# M2Sxxx register map
Vendor: Microsemi; Series: SmartFusion2; File version: 2.0.32
CPU: CM3 r2p1, little endian, MPU, no FPU, 4 interrupt priority bits
Registers are 32-bit, read-write, no defined reset value unless marked. A register's access mark holds for its fields unless they carry their own. Offsets are from the block's base; [hi:lo] are bit positions; {n}, {i} and the like mark numbered series; 'fields as' and 'values as' point back to an identical list.

## MMUART_0 — No description provided for this peripheral
Base 0x40000000
Same registers: MMUART_1 0x40010000
0x00 RBR — Receiver buffer register
  [12] RBR ro — This register holds the receive data bits for MMUART_x. The default value is unknown since the register is loaded with data in the receive FIFO. Bit 0 is the LSB and it is the first bit received. It may be configured as the MSB by configuring the E_MSB_RX bit in the MM1. The divisor latch access bit (DLAB), bit 7 of LCR, must be 0 to read this register. This register is read only. Writing to this register with the DLAB 0 changes the transmit holding register (THR) register value.
0x00 THR (alternate view of RBR) — Transmit holding register
  [7:0] THR wo — This register holds the data bits to be transmitted. Bit 0 is the LSB and is transmitted first. The MSB may be transmitted first, if it is configured with the E_MSB_TX bit in the MM1. The reset value is unknown since the register is loaded with data in the transmit FIFO. The DLAB, bit 7 of LCR, must be 0 to write to this register. This register is write only. Reading from this register with the DLAB 0 reads the RBR register value.
0x00 DLR (alternate view of RBR) — Divisor latch (LSB)
  [7:0] DLR — This divisor latch LSB register (DLR) holds the LSB of the integer divisor value used to calculate the baud rate. The baud rate can be calculated using EQ 1, 2, 3, or 4.
0x04 DMR — Divisor latch (MSB)
  [7:0] DMR — This divisor latch MSB register (DMR) holds the MSB of the integer divisor value used to calculate the baud rate. The baud rate can be calculated using EQ 1, 2, 3, or 4.
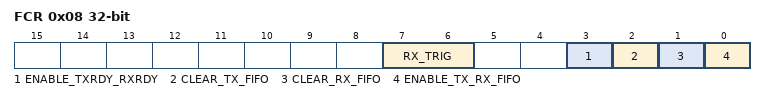
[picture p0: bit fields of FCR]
0x08 FCR — FIFO control register
  [7:6] RX_TRIG wo — These bits are used to set the trigger level for the Rx FIFO interrupt. Rx FIFO trigger level (bytes) are: 0b00: 1 byte 0b01: 4 bytes 0b10: 8 bytes 0b11: 14 bytes
  [3] ENABLE_TXRDY_RXRDY wo — Software must always set this bit to 1 for efficient data transfer from transmit FIFO to PDMA.
  [2] CLEAR_TX_FIFO wo — Clears all bytes in the Tx FIFO and resets its counter logic. The shift register is not cleared. 0: Disabled (default) 1: Enabled
  [1] CLEAR_RX_FIFO wo — Clears all bytes in Rx FIFO and resets counter logic. This shift register is not cleared. 0: Disabled (default) 1: Enabled
  [0] ENABLE_TX_RX_FIFO wo — It enables both the Tx and Rx FIFOs and is hardwired to 1, which means it is always enabled and cannot be changed.

## GPIO — No description provided for this peripheral
Base 0x40013000
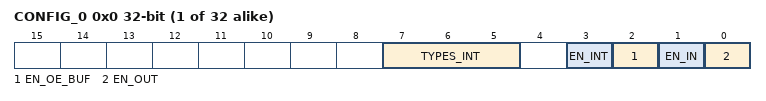
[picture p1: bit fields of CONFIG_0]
{0x0+4i} CONFIG_{i} (i=0..31) — No description provided for this register
  [7:5] TYPES_INT — No description provided for this field
  [3] EN_INT — No description provided for this field
  [2] EN_OE_BUF — No description provided for this field
  [1] EN_IN — No description provided for this field
  [0] EN_OUT — No description provided for this field
0x80 INTR — No description provided for this register
  [0] No_field_names_or_bit_ranges_assigned_yet — No description provided for this field
0x84 GPIN — No description provided for this register
  [0] No_field_names_or_bit_ranges_assigned_yet ro — No description provided for this field
0x88 GPOUT — No description provided for this register
  fields as INTR

## Watchdog — No description provided for this peripheral
Base 0x40005000
0x00 WDOG_VALUE — No description provided for this register
  [31:0] WDOGVALUE ro — No description provided for this field
0x04 WDOG_LOAD — No description provided for this register
  [31:0] WDOGLOAD ro — No description provided for this field
0x08 WDOG_MVRP — No description provided for this register
  [31:0] WDOGMVRP ro — No description provided for this field
0x0C WDOG_REFRESH — No description provided for this register
  [31:0] WDOGREFRESH wo — No description provided for this field
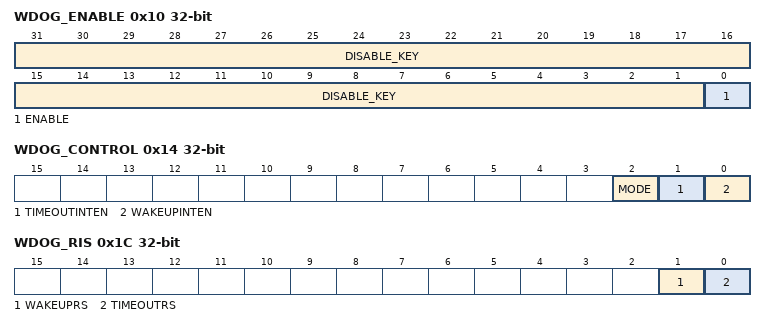
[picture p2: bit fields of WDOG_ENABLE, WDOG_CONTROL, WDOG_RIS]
0x10 WDOG_ENABLE — No description provided for this register
  [31:1] DISABLE_KEY ro — No description provided for this field
  [0] ENABLE ro — No description provided for this field
0x14 WDOG_CONTROL — No description provided for this register
  [2] MODE — No description provided for this field
  [1] TIMEOUTINTEN — No description provided for this field
  [0] WAKEUPINTEN — No description provided for this field
0x18 WDOG_STATUS — No description provided for this register
  [0] REFRESHSTATUS ro — No description provided for this field
0x1C WDOG_RIS — No description provided for this register
  [1] WAKEUPRS — No description provided for this field
  [0] TIMEOUTRS — No description provided for this field
